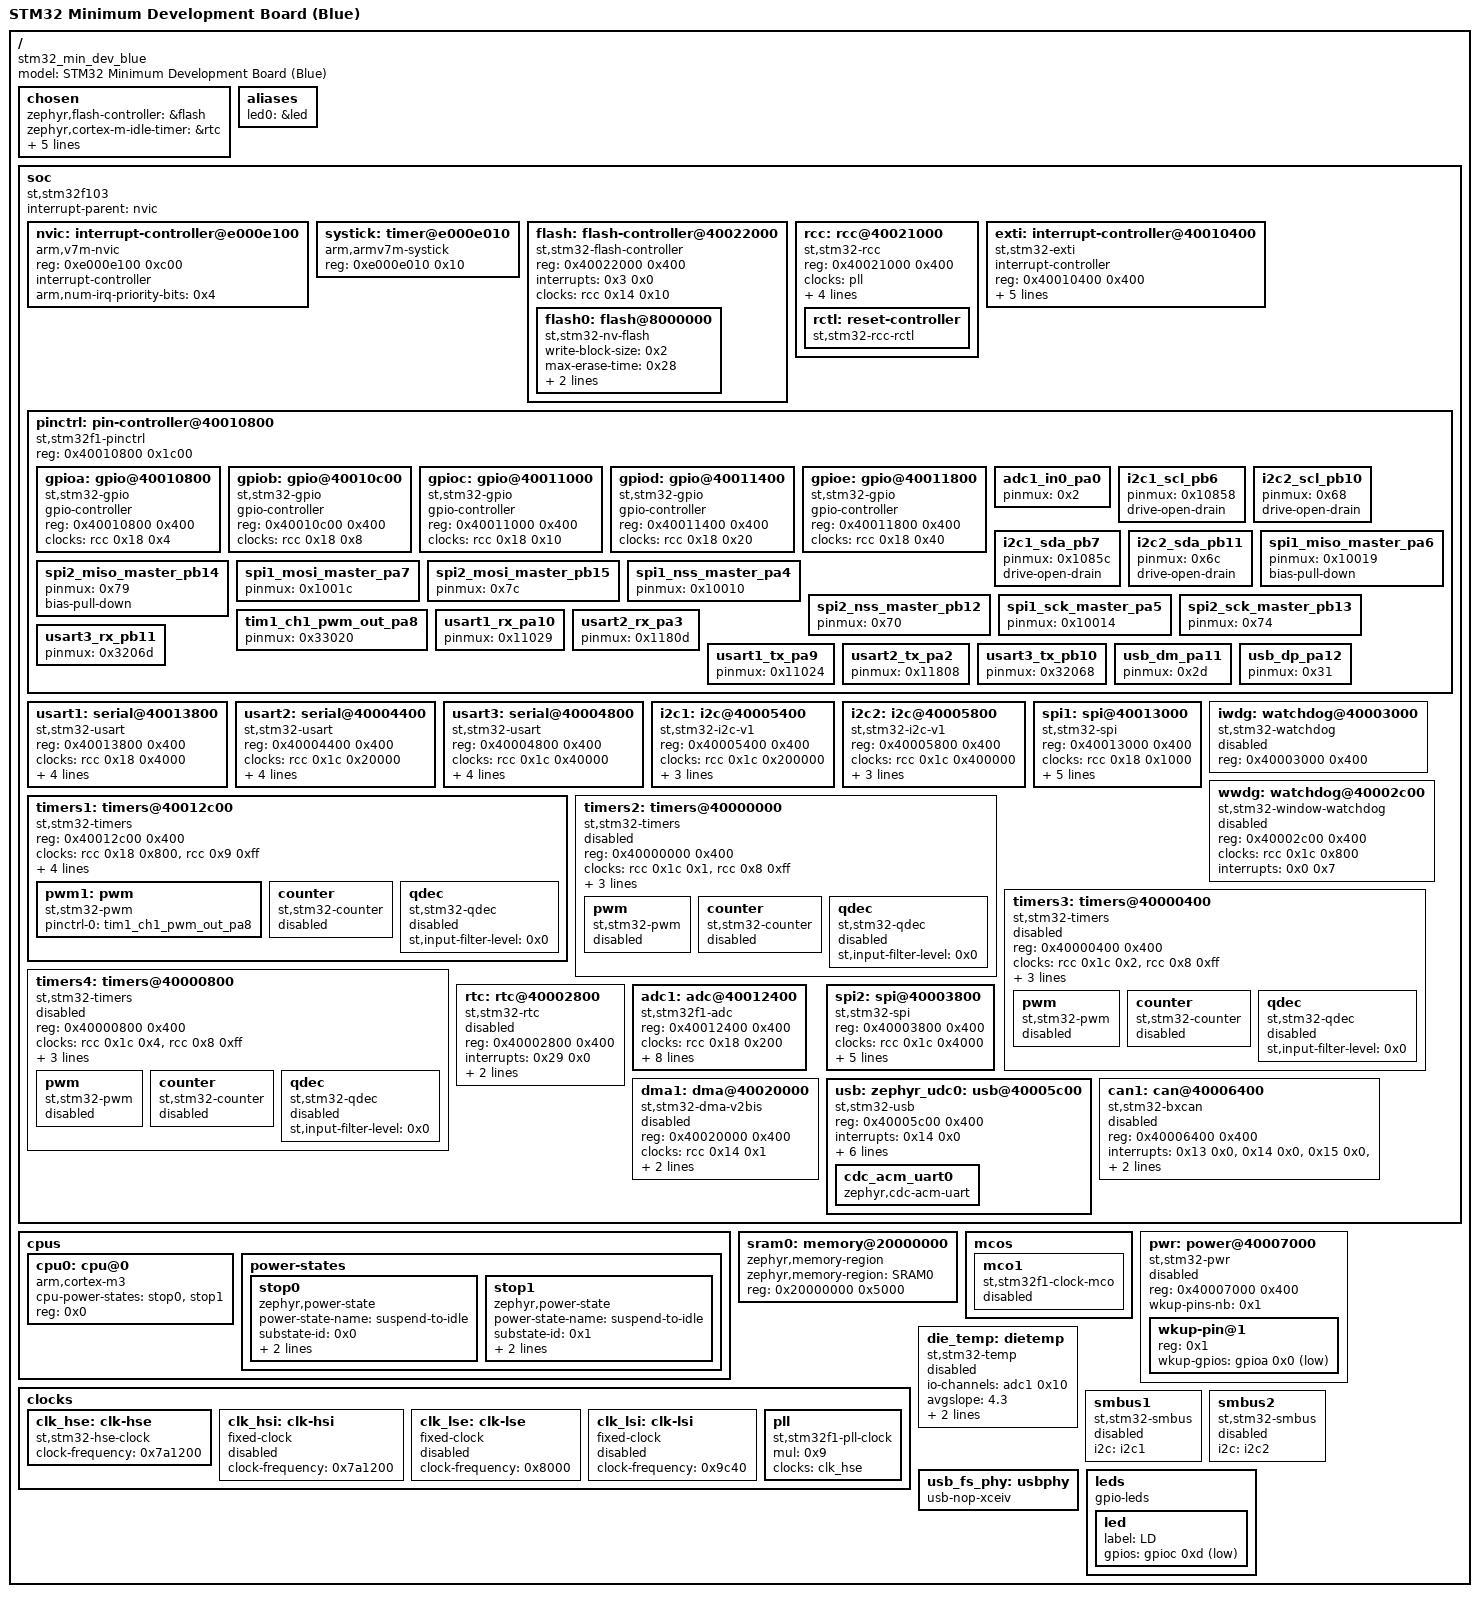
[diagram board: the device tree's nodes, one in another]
/dts-v1/;

/* node '/' defined in zephyr/dts/common/skeleton.dtsi:9 */
/ {
	#address-cells = < 0x1 >;                         /* in zephyr/dts/common/skeleton.dtsi:10 */
	#size-cells = < 0x1 >;                            /* in zephyr/dts/common/skeleton.dtsi:11 */
	model = "STM32 Minimum Development Board (Blue)"; /* in zephyr/boards/others/stm32_min_dev/stm32_min_dev_stm32f103xb_blue.overlay:8 */
	compatible = "stm32_min_dev_blue",
	             "st,stm32f103c8";                    /* in zephyr/boards/others/stm32_min_dev/stm32_min_dev_stm32f103xb_blue.overlay:9 */

	/* node '/chosen' defined in zephyr/dts/common/skeleton.dtsi:13 */
	chosen {
		zephyr,flash-controller = &flash;   /* in zephyr/dts/arm/st/f1/stm32f1.dtsi:24 */
		zephyr,cortex-m-idle-timer = &rtc;  /* in zephyr/dts/arm/st/f1/stm32f1.dtsi:25 */
		zephyr,osdp-uart = &usart2;         /* in zephyr/boards/others/stm32_min_dev/stm32_min_dev.dts:18 */
		zephyr,sram = &sram0;               /* in zephyr/boards/others/stm32_min_dev/stm32_min_dev.dts:19 */
		zephyr,flash = &flash0;             /* in zephyr/boards/others/stm32_min_dev/stm32_min_dev.dts:20 */
		zephyr,console = &cdc_acm_uart0;    /* in zephyer_stm32f103_blink/app.overlay:3 */
		zephyr,shell-uart = &cdc_acm_uart0; /* in zephyer_stm32f103_blink/app.overlay:4 */
	};

	/* node '/aliases' defined in zephyr/dts/common/skeleton.dtsi:15 */
	aliases {
		led0 = &led; /* in zephyr/boards/others/stm32_min_dev/stm32_min_dev.dts:33 */
	};

	/* node '/soc' defined in zephyr/dts/arm/armv7-m.dtsi:6 */
	soc {
		#address-cells = < 0x1 >;     /* in zephyr/dts/arm/armv7-m.dtsi:7 */
		#size-cells = < 0x1 >;        /* in zephyr/dts/arm/armv7-m.dtsi:8 */
		interrupt-parent = < &nvic >; /* in zephyr/dts/arm/armv7-m.dtsi:10 */
		ranges;                       /* in zephyr/dts/arm/armv7-m.dtsi:11 */
		compatible = "st,stm32f103",
		             "st,stm32f1",
		             "simple-bus";    /* in zephyr/dts/arm/st/f1/stm32f103X8.dtsi:15 */

		/* node '/soc/interrupt-controller@e000e100' defined in zephyr/dts/arm/armv7-m.dtsi:13 */
		nvic: interrupt-controller@e000e100 {
			#address-cells = < 0x1 >;            /* in zephyr/dts/arm/armv7-m.dtsi:14 */
			compatible = "arm,v7m-nvic";         /* in zephyr/dts/arm/armv7-m.dtsi:15 */
			reg = < 0xe000e100 0xc00 >;          /* in zephyr/dts/arm/armv7-m.dtsi:16 */
			interrupt-controller;                /* in zephyr/dts/arm/armv7-m.dtsi:17 */
			#interrupt-cells = < 0x2 >;          /* in zephyr/dts/arm/armv7-m.dtsi:18 */
			arm,num-irq-priority-bits = < 0x4 >; /* in zephyr/dts/arm/st/f1/stm32f1.dtsi:466 */
			phandle = < 0x1 >;                   /* in zephyr/dts/arm/armv7-m.dtsi:10 */
		};

		/* node '/soc/timer@e000e010' defined in zephyr/dts/arm/armv7-m.dtsi:21 */
		systick: timer@e000e010 {
			compatible = "arm,armv7m-systick"; /* in zephyr/dts/arm/armv7-m.dtsi:22 */
			reg = < 0xe000e010 0x10 >;         /* in zephyr/dts/arm/armv7-m.dtsi:23 */
		};

		/* node '/soc/flash-controller@40022000' defined in zephyr/dts/arm/st/f1/stm32f1.dtsi:106 */
		flash: flash-controller@40022000 {
			compatible = "st,stm32-flash-controller",
			             "st,stm32f1-flash-controller"; /* in zephyr/dts/arm/st/f1/stm32f1.dtsi:107 */
			reg = < 0x40022000 0x400 >;                 /* in zephyr/dts/arm/st/f1/stm32f1.dtsi:108 */
			interrupts = < 0x3 0x0 >;                   /* in zephyr/dts/arm/st/f1/stm32f1.dtsi:109 */
			clocks = < &rcc 0x14 0x10 >;                /* in zephyr/dts/arm/st/f1/stm32f1.dtsi:110 */
			#address-cells = < 0x1 >;                   /* in zephyr/dts/arm/st/f1/stm32f1.dtsi:112 */
			#size-cells = < 0x1 >;                      /* in zephyr/dts/arm/st/f1/stm32f1.dtsi:113 */

			/* node '/soc/flash-controller@40022000/flash@8000000' defined in zephyr/dts/arm/st/f1/stm32f1.dtsi:115 */
			flash0: flash@8000000 {
				compatible = "st,stm32-nv-flash",
				             "soc-nv-flash";      /* in zephyr/dts/arm/st/f1/stm32f1.dtsi:116 */
				write-block-size = < 0x2 >;       /* in zephyr/dts/arm/st/f1/stm32f1.dtsi:118 */
				max-erase-time = < 0x28 >;        /* in zephyr/dts/arm/st/f1/stm32f1.dtsi:120 */
				reg = < 0x8000000 0x10000 >;      /* in zephyr/dts/arm/st/f1/stm32f103X8.dtsi:19 */
				erase-block-size = < 0x400 >;     /* in zephyr/dts/arm/st/f1/stm32f103X8.dtsi:20 */
			};
		};

		/* node '/soc/rcc@40021000' defined in zephyr/dts/arm/st/f1/stm32f1.dtsi:124 */
		rcc: rcc@40021000 {
			compatible = "st,stm32-rcc";     /* in zephyr/dts/arm/st/f1/stm32f1.dtsi:125 */
			#clock-cells = < 0x2 >;          /* in zephyr/dts/arm/st/f1/stm32f1.dtsi:126 */
			reg = < 0x40021000 0x400 >;      /* in zephyr/dts/arm/st/f1/stm32f1.dtsi:127 */
			clocks = < &pll >;               /* in zephyr/boards/others/stm32_min_dev/stm32_min_dev.dts:49 */
			clock-frequency = < 0x44aa200 >; /* in zephyr/boards/others/stm32_min_dev/stm32_min_dev.dts:50 */
			ahb-prescaler = < 0x1 >;         /* in zephyr/boards/others/stm32_min_dev/stm32_min_dev.dts:51 */
			apb1-prescaler = < 0x2 >;        /* in zephyr/boards/others/stm32_min_dev/stm32_min_dev.dts:52 */
			apb2-prescaler = < 0x1 >;        /* in zephyr/boards/others/stm32_min_dev/stm32_min_dev.dts:53 */
			phandle = < 0x2 >;               /* in zephyr/dts/arm/st/f1/stm32f1.dtsi:110 */

			/* node '/soc/rcc@40021000/reset-controller' defined in zephyr/dts/arm/st/f1/stm32f1.dtsi:129 */
			rctl: reset-controller {
				compatible = "st,stm32-rcc-rctl"; /* in zephyr/dts/arm/st/f1/stm32f1.dtsi:130 */
				#reset-cells = < 0x1 >;           /* in zephyr/dts/arm/st/f1/stm32f1.dtsi:131 */
				phandle = < 0x4 >;                /* in zephyr/dts/arm/st/f1/stm32f1.dtsi:201 */
			};
		};

		/* node '/soc/interrupt-controller@40010400' defined in zephyr/dts/arm/st/f1/stm32f1.dtsi:135 */
		exti: interrupt-controller@40010400 {
			compatible = "st,stm32-exti";  /* in zephyr/dts/arm/st/f1/stm32f1.dtsi:136 */
			interrupt-controller;          /* in zephyr/dts/arm/st/f1/stm32f1.dtsi:137 */
			#interrupt-cells = < 0x1 >;    /* in zephyr/dts/arm/st/f1/stm32f1.dtsi:138 */
			#address-cells = < 0x0 >;      /* in zephyr/dts/arm/st/f1/stm32f1.dtsi:139 */
			reg = < 0x40010400 0x400 >;    /* in zephyr/dts/arm/st/f1/stm32f1.dtsi:140 */
			num-lines = < 0x20 >;          /* in zephyr/dts/arm/st/f1/stm32f1.dtsi:141 */
			interrupts = < 0x6 0x0 >,
			             < 0x7 0x0 >,
			             < 0x8 0x0 >,
			             < 0x9 0x0 >,
			             < 0xa 0x0 >,
			             < 0x17 0x0 >,
			             < 0x28 0x0 >;     /* in zephyr/dts/arm/st/f1/stm32f1.dtsi:142 */
			interrupt-names = "line0",
			                  "line1",
			                  "line2",
			                  "line3",
			                  "line4",
			                  "line5-9",
			                  "line10-15"; /* in zephyr/dts/arm/st/f1/stm32f1.dtsi:144 */
			line-ranges = < 0x0 0x1 >,
			              < 0x1 0x1 >,
			              < 0x2 0x1 >,
			              < 0x3 0x1 >,
			              < 0x4 0x1 >,
			              < 0x5 0x5 >,
			              < 0xa 0x6 >;     /* in zephyr/dts/arm/st/f1/stm32f1.dtsi:146 */
		};

		/* node '/soc/pin-controller@40010800' defined in zephyr/dts/arm/st/f1/stm32f1.dtsi:150 */
		pinctrl: pin-controller@40010800 {
			compatible = "st,stm32f1-pinctrl"; /* in zephyr/dts/arm/st/f1/stm32f1.dtsi:151 */
			#address-cells = < 0x1 >;          /* in zephyr/dts/arm/st/f1/stm32f1.dtsi:152 */
			#size-cells = < 0x1 >;             /* in zephyr/dts/arm/st/f1/stm32f1.dtsi:153 */
			reg = < 0x40010800 0x1c00 >;       /* in zephyr/dts/arm/st/f1/stm32f1.dtsi:154 */

			/* node '/soc/pin-controller@40010800/gpio@40010800' defined in zephyr/dts/arm/st/f1/stm32f1.dtsi:156 */
			gpioa: gpio@40010800 {
				compatible = "st,stm32-gpio"; /* in zephyr/dts/arm/st/f1/stm32f1.dtsi:157 */
				gpio-controller;              /* in zephyr/dts/arm/st/f1/stm32f1.dtsi:158 */
				#gpio-cells = < 0x2 >;        /* in zephyr/dts/arm/st/f1/stm32f1.dtsi:159 */
				reg = < 0x40010800 0x400 >;   /* in zephyr/dts/arm/st/f1/stm32f1.dtsi:160 */
				clocks = < &rcc 0x18 0x4 >;   /* in zephyr/dts/arm/st/f1/stm32f1.dtsi:161 */
				phandle = < 0x1f >;           /* in zephyr/dts/arm/st/f1/stm32f1.dtsi:435 */
			};

			/* node '/soc/pin-controller@40010800/gpio@40010c00' defined in zephyr/dts/arm/st/f1/stm32f1.dtsi:164 */
			gpiob: gpio@40010c00 {
				compatible = "st,stm32-gpio"; /* in zephyr/dts/arm/st/f1/stm32f1.dtsi:165 */
				gpio-controller;              /* in zephyr/dts/arm/st/f1/stm32f1.dtsi:166 */
				#gpio-cells = < 0x2 >;        /* in zephyr/dts/arm/st/f1/stm32f1.dtsi:167 */
				reg = < 0x40010c00 0x400 >;   /* in zephyr/dts/arm/st/f1/stm32f1.dtsi:168 */
				clocks = < &rcc 0x18 0x8 >;   /* in zephyr/dts/arm/st/f1/stm32f1.dtsi:169 */
			};

			/* node '/soc/pin-controller@40010800/gpio@40011000' defined in zephyr/dts/arm/st/f1/stm32f1.dtsi:172 */
			gpioc: gpio@40011000 {
				compatible = "st,stm32-gpio"; /* in zephyr/dts/arm/st/f1/stm32f1.dtsi:173 */
				gpio-controller;              /* in zephyr/dts/arm/st/f1/stm32f1.dtsi:174 */
				#gpio-cells = < 0x2 >;        /* in zephyr/dts/arm/st/f1/stm32f1.dtsi:175 */
				reg = < 0x40011000 0x400 >;   /* in zephyr/dts/arm/st/f1/stm32f1.dtsi:176 */
				clocks = < &rcc 0x18 0x10 >;  /* in zephyr/dts/arm/st/f1/stm32f1.dtsi:177 */
				phandle = < 0x23 >;           /* in zephyr/boards/others/stm32_min_dev/stm32_min_dev_stm32f103xb_blue.overlay:13 */
			};

			/* node '/soc/pin-controller@40010800/gpio@40011400' defined in zephyr/dts/arm/st/f1/stm32f1.dtsi:180 */
			gpiod: gpio@40011400 {
				compatible = "st,stm32-gpio"; /* in zephyr/dts/arm/st/f1/stm32f1.dtsi:181 */
				gpio-controller;              /* in zephyr/dts/arm/st/f1/stm32f1.dtsi:182 */
				#gpio-cells = < 0x2 >;        /* in zephyr/dts/arm/st/f1/stm32f1.dtsi:183 */
				reg = < 0x40011400 0x400 >;   /* in zephyr/dts/arm/st/f1/stm32f1.dtsi:184 */
				clocks = < &rcc 0x18 0x20 >;  /* in zephyr/dts/arm/st/f1/stm32f1.dtsi:185 */
			};

			/* node '/soc/pin-controller@40010800/gpio@40011800' defined in zephyr/dts/arm/st/f1/stm32f1.dtsi:188 */
			gpioe: gpio@40011800 {
				compatible = "st,stm32-gpio"; /* in zephyr/dts/arm/st/f1/stm32f1.dtsi:189 */
				gpio-controller;              /* in zephyr/dts/arm/st/f1/stm32f1.dtsi:190 */
				#gpio-cells = < 0x2 >;        /* in zephyr/dts/arm/st/f1/stm32f1.dtsi:191 */
				reg = < 0x40011800 0x400 >;   /* in zephyr/dts/arm/st/f1/stm32f1.dtsi:192 */
				clocks = < &rcc 0x18 0x40 >;  /* in zephyr/dts/arm/st/f1/stm32f1.dtsi:193 */
			};

			/* node '/soc/pin-controller@40010800/adc1_in0_pa0' defined in modules/hal/stm32/dts/st/f1/stm32f103r(8-b)tx-pinctrl.dtsi:15 */
			adc1_in0_pa0: adc1_in0_pa0 {
				pinmux = < 0x2 >;   /* in modules/hal/stm32/dts/st/f1/stm32f103r(8-b)tx-pinctrl.dtsi:16 */
				phandle = < 0x14 >; /* in zephyr/boards/others/stm32_min_dev/stm32_min_dev.dts:123 */
			};

			/* node '/soc/pin-controller@40010800/i2c1_scl_pb6' defined in modules/hal/stm32/dts/st/f1/stm32f103r(8-b)tx-pinctrl.dtsi:371 */
			i2c1_scl_pb6: i2c1_scl_pb6 {
				pinmux = < 0x10858 >; /* in modules/hal/stm32/dts/st/f1/stm32f103r(8-b)tx-pinctrl.dtsi:372 */
				drive-open-drain;     /* in modules/hal/stm32/dts/st/f1/stm32f103r(8-b)tx-pinctrl.dtsi:373 */
				phandle = < 0xb >;    /* in zephyr/boards/others/stm32_min_dev/stm32_min_dev.dts:79 */
			};

			/* node '/soc/pin-controller@40010800/i2c2_scl_pb10' defined in modules/hal/stm32/dts/st/f1/stm32f103r(8-b)tx-pinctrl.dtsi:381 */
			i2c2_scl_pb10: i2c2_scl_pb10 {
				pinmux = < 0x68 >; /* in modules/hal/stm32/dts/st/f1/stm32f103r(8-b)tx-pinctrl.dtsi:382 */
				drive-open-drain;  /* in modules/hal/stm32/dts/st/f1/stm32f103r(8-b)tx-pinctrl.dtsi:383 */
				phandle = < 0xd >; /* in zephyr/boards/others/stm32_min_dev/stm32_min_dev.dts:86 */
			};

			/* node '/soc/pin-controller@40010800/i2c1_sda_pb7' defined in modules/hal/stm32/dts/st/f1/stm32f103r(8-b)tx-pinctrl.dtsi:388 */
			i2c1_sda_pb7: i2c1_sda_pb7 {
				pinmux = < 0x1085c >; /* in modules/hal/stm32/dts/st/f1/stm32f103r(8-b)tx-pinctrl.dtsi:389 */
				drive-open-drain;     /* in modules/hal/stm32/dts/st/f1/stm32f103r(8-b)tx-pinctrl.dtsi:390 */
				phandle = < 0xc >;    /* in zephyr/boards/others/stm32_min_dev/stm32_min_dev.dts:79 */
			};

			/* node '/soc/pin-controller@40010800/i2c2_sda_pb11' defined in modules/hal/stm32/dts/st/f1/stm32f103r(8-b)tx-pinctrl.dtsi:398 */
			i2c2_sda_pb11: i2c2_sda_pb11 {
				pinmux = < 0x6c >; /* in modules/hal/stm32/dts/st/f1/stm32f103r(8-b)tx-pinctrl.dtsi:399 */
				drive-open-drain;  /* in modules/hal/stm32/dts/st/f1/stm32f103r(8-b)tx-pinctrl.dtsi:400 */
				phandle = < 0xe >; /* in zephyr/boards/others/stm32_min_dev/stm32_min_dev.dts:86 */
			};

			/* node '/soc/pin-controller@40010800/spi1_miso_master_pa6' defined in modules/hal/stm32/dts/st/f1/stm32f103r(8-b)tx-pinctrl.dtsi:439 */
			spi1_miso_master_pa6: spi1_miso_master_pa6 {
				pinmux = < 0x10019 >; /* in modules/hal/stm32/dts/st/f1/stm32f103r(8-b)tx-pinctrl.dtsi:440 */
				bias-pull-down;       /* in modules/hal/stm32/dts/st/f1/stm32f103r(8-b)tx-pinctrl.dtsi:441 */
				phandle = < 0x11 >;   /* in zephyr/boards/others/stm32_min_dev/stm32_min_dev.dts:93 */
			};

			/* node '/soc/pin-controller@40010800/spi2_miso_master_pb14' defined in modules/hal/stm32/dts/st/f1/stm32f103r(8-b)tx-pinctrl.dtsi:449 */
			spi2_miso_master_pb14: spi2_miso_master_pb14 {
				pinmux = < 0x79 >;  /* in modules/hal/stm32/dts/st/f1/stm32f103r(8-b)tx-pinctrl.dtsi:450 */
				bias-pull-down;     /* in modules/hal/stm32/dts/st/f1/stm32f103r(8-b)tx-pinctrl.dtsi:451 */
				phandle = < 0x17 >; /* in zephyr/boards/others/stm32_min_dev/stm32_min_dev.dts:100 */
			};

			/* node '/soc/pin-controller@40010800/spi1_mosi_master_pa7' defined in modules/hal/stm32/dts/st/f1/stm32f103r(8-b)tx-pinctrl.dtsi:456 */
			spi1_mosi_master_pa7: spi1_mosi_master_pa7 {
				pinmux = < 0x1001c >; /* in modules/hal/stm32/dts/st/f1/stm32f103r(8-b)tx-pinctrl.dtsi:457 */
				phandle = < 0x12 >;   /* in zephyr/boards/others/stm32_min_dev/stm32_min_dev.dts:93 */
			};

			/* node '/soc/pin-controller@40010800/spi2_mosi_master_pb15' defined in modules/hal/stm32/dts/st/f1/stm32f103r(8-b)tx-pinctrl.dtsi:464 */
			spi2_mosi_master_pb15: spi2_mosi_master_pb15 {
				pinmux = < 0x7c >;  /* in modules/hal/stm32/dts/st/f1/stm32f103r(8-b)tx-pinctrl.dtsi:465 */
				phandle = < 0x18 >; /* in zephyr/boards/others/stm32_min_dev/stm32_min_dev.dts:100 */
			};

			/* node '/soc/pin-controller@40010800/spi1_nss_master_pa4' defined in modules/hal/stm32/dts/st/f1/stm32f103r(8-b)tx-pinctrl.dtsi:470 */
			spi1_nss_master_pa4: spi1_nss_master_pa4 {
				pinmux = < 0x10010 >; /* in modules/hal/stm32/dts/st/f1/stm32f103r(8-b)tx-pinctrl.dtsi:471 */
				phandle = < 0xf >;    /* in zephyr/boards/others/stm32_min_dev/stm32_min_dev.dts:93 */
			};

			/* node '/soc/pin-controller@40010800/spi2_nss_master_pb12' defined in modules/hal/stm32/dts/st/f1/stm32f103r(8-b)tx-pinctrl.dtsi:478 */
			spi2_nss_master_pb12: spi2_nss_master_pb12 {
				pinmux = < 0x70 >;  /* in modules/hal/stm32/dts/st/f1/stm32f103r(8-b)tx-pinctrl.dtsi:479 */
				phandle = < 0x15 >; /* in zephyr/boards/others/stm32_min_dev/stm32_min_dev.dts:100 */
			};

			/* node '/soc/pin-controller@40010800/spi1_sck_master_pa5' defined in modules/hal/stm32/dts/st/f1/stm32f103r(8-b)tx-pinctrl.dtsi:484 */
			spi1_sck_master_pa5: spi1_sck_master_pa5 {
				pinmux = < 0x10014 >; /* in modules/hal/stm32/dts/st/f1/stm32f103r(8-b)tx-pinctrl.dtsi:485 */
				phandle = < 0x10 >;   /* in zephyr/boards/others/stm32_min_dev/stm32_min_dev.dts:93 */
			};

			/* node '/soc/pin-controller@40010800/spi2_sck_master_pb13' defined in modules/hal/stm32/dts/st/f1/stm32f103r(8-b)tx-pinctrl.dtsi:492 */
			spi2_sck_master_pb13: spi2_sck_master_pb13 {
				pinmux = < 0x74 >;  /* in modules/hal/stm32/dts/st/f1/stm32f103r(8-b)tx-pinctrl.dtsi:493 */
				phandle = < 0x16 >; /* in zephyr/boards/others/stm32_min_dev/stm32_min_dev.dts:100 */
			};

			/* node '/soc/pin-controller@40010800/tim1_ch1_pwm_out_pa8' defined in modules/hal/stm32/dts/st/f1/stm32f103r(8-b)tx-pinctrl.dtsi:757 */
			tim1_ch1_pwm_out_pa8: tim1_ch1_pwm_out_pa8 {
				pinmux = < 0x33020 >; /* in modules/hal/stm32/dts/st/f1/stm32f103r(8-b)tx-pinctrl.dtsi:758 */
				phandle = < 0x13 >;   /* in zephyr/boards/others/stm32_min_dev/stm32_min_dev.dts:111 */
			};

			/* node '/soc/pin-controller@40010800/usart1_rx_pa10' defined in modules/hal/stm32/dts/st/f1/stm32f103r(8-b)tx-pinctrl.dtsi:983 */
			usart1_rx_pa10: usart1_rx_pa10 {
				pinmux = < 0x11029 >; /* in modules/hal/stm32/dts/st/f1/stm32f103r(8-b)tx-pinctrl.dtsi:984 */
				phandle = < 0x6 >;    /* in zephyr/boards/others/stm32_min_dev/stm32_min_dev.dts:58 */
			};

			/* node '/soc/pin-controller@40010800/usart2_rx_pa3' defined in modules/hal/stm32/dts/st/f1/stm32f103r(8-b)tx-pinctrl.dtsi:991 */
			usart2_rx_pa3: usart2_rx_pa3 {
				pinmux = < 0x1180d >; /* in modules/hal/stm32/dts/st/f1/stm32f103r(8-b)tx-pinctrl.dtsi:992 */
				phandle = < 0x8 >;    /* in zephyr/boards/others/stm32_min_dev/stm32_min_dev.dts:65 */
			};

			/* node '/soc/pin-controller@40010800/usart3_rx_pb11' defined in modules/hal/stm32/dts/st/f1/stm32f103r(8-b)tx-pinctrl.dtsi:995 */
			usart3_rx_pb11: usart3_rx_pb11 {
				pinmux = < 0x3206d >; /* in modules/hal/stm32/dts/st/f1/stm32f103r(8-b)tx-pinctrl.dtsi:996 */
				phandle = < 0xa >;    /* in zephyr/boards/others/stm32_min_dev/stm32_min_dev.dts:72 */
			};

			/* node '/soc/pin-controller@40010800/usart1_tx_pa9' defined in modules/hal/stm32/dts/st/f1/stm32f103r(8-b)tx-pinctrl.dtsi:1005 */
			usart1_tx_pa9: usart1_tx_pa9 {
				pinmux = < 0x11024 >; /* in modules/hal/stm32/dts/st/f1/stm32f103r(8-b)tx-pinctrl.dtsi:1006 */
				phandle = < 0x5 >;    /* in zephyr/boards/others/stm32_min_dev/stm32_min_dev.dts:58 */
			};

			/* node '/soc/pin-controller@40010800/usart2_tx_pa2' defined in modules/hal/stm32/dts/st/f1/stm32f103r(8-b)tx-pinctrl.dtsi:1013 */
			usart2_tx_pa2: usart2_tx_pa2 {
				pinmux = < 0x11808 >; /* in modules/hal/stm32/dts/st/f1/stm32f103r(8-b)tx-pinctrl.dtsi:1014 */
				phandle = < 0x7 >;    /* in zephyr/boards/others/stm32_min_dev/stm32_min_dev.dts:65 */
			};

			/* node '/soc/pin-controller@40010800/usart3_tx_pb10' defined in modules/hal/stm32/dts/st/f1/stm32f103r(8-b)tx-pinctrl.dtsi:1017 */
			usart3_tx_pb10: usart3_tx_pb10 {
				pinmux = < 0x32068 >; /* in modules/hal/stm32/dts/st/f1/stm32f103r(8-b)tx-pinctrl.dtsi:1018 */
				phandle = < 0x9 >;    /* in zephyr/boards/others/stm32_min_dev/stm32_min_dev.dts:72 */
			};

			/* node '/soc/pin-controller@40010800/usb_dm_pa11' defined in modules/hal/stm32/dts/st/f1/stm32f103r(8-b)tx-pinctrl.dtsi:1027 */
			usb_dm_pa11: usb_dm_pa11 {
				pinmux = < 0x2d >;  /* in modules/hal/stm32/dts/st/f1/stm32f103r(8-b)tx-pinctrl.dtsi:1028 */
				phandle = < 0x1a >; /* in zephyr/boards/others/stm32_min_dev/stm32_min_dev.dts:117 */
			};

			/* node '/soc/pin-controller@40010800/usb_dp_pa12' defined in modules/hal/stm32/dts/st/f1/stm32f103r(8-b)tx-pinctrl.dtsi:1031 */
			usb_dp_pa12: usb_dp_pa12 {
				pinmux = < 0x31 >;  /* in modules/hal/stm32/dts/st/f1/stm32f103r(8-b)tx-pinctrl.dtsi:1032 */
				phandle = < 0x1b >; /* in zephyr/boards/others/stm32_min_dev/stm32_min_dev.dts:117 */
			};
		};

		/* node '/soc/serial@40013800' defined in zephyr/dts/arm/st/f1/stm32f1.dtsi:197 */
		usart1: serial@40013800 {
			compatible = "st,stm32-usart",
			             "st,stm32-uart";                   /* in zephyr/dts/arm/st/f1/stm32f1.dtsi:198 */
			reg = < 0x40013800 0x400 >;                     /* in zephyr/dts/arm/st/f1/stm32f1.dtsi:199 */
			clocks = < &rcc 0x18 0x4000 >;                  /* in zephyr/dts/arm/st/f1/stm32f1.dtsi:200 */
			resets = < &rctl 0x18e >;                       /* in zephyr/dts/arm/st/f1/stm32f1.dtsi:201 */
			interrupts = < 0x25 0x0 >;                      /* in zephyr/dts/arm/st/f1/stm32f1.dtsi:202 */
			pinctrl-0 = < &usart1_tx_pa9 &usart1_rx_pa10 >; /* in zephyr/boards/others/stm32_min_dev/stm32_min_dev.dts:58 */
			current-speed = < 0x1c200 >;                    /* in zephyr/boards/others/stm32_min_dev/stm32_min_dev.dts:59 */
			pinctrl-names = "default";                      /* in zephyr/boards/others/stm32_min_dev/stm32_min_dev.dts:60 */
			status = "okay";                                /* in zephyr/boards/others/stm32_min_dev/stm32_min_dev.dts:61 */
		};

		/* node '/soc/serial@40004400' defined in zephyr/dts/arm/st/f1/stm32f1.dtsi:206 */
		usart2: serial@40004400 {
			compatible = "st,stm32-usart",
			             "st,stm32-uart";                  /* in zephyr/dts/arm/st/f1/stm32f1.dtsi:207 */
			reg = < 0x40004400 0x400 >;                    /* in zephyr/dts/arm/st/f1/stm32f1.dtsi:208 */
			clocks = < &rcc 0x1c 0x20000 >;                /* in zephyr/dts/arm/st/f1/stm32f1.dtsi:209 */
			resets = < &rctl 0x211 >;                      /* in zephyr/dts/arm/st/f1/stm32f1.dtsi:210 */
			interrupts = < 0x26 0x0 >;                     /* in zephyr/dts/arm/st/f1/stm32f1.dtsi:211 */
			pinctrl-0 = < &usart2_tx_pa2 &usart2_rx_pa3 >; /* in zephyr/boards/others/stm32_min_dev/stm32_min_dev.dts:65 */
			current-speed = < 0x1c200 >;                   /* in zephyr/boards/others/stm32_min_dev/stm32_min_dev.dts:66 */
			pinctrl-names = "default";                     /* in zephyr/boards/others/stm32_min_dev/stm32_min_dev.dts:67 */
			status = "okay";                               /* in zephyr/boards/others/stm32_min_dev/stm32_min_dev.dts:68 */
		};

		/* node '/soc/serial@40004800' defined in zephyr/dts/arm/st/f1/stm32f1.dtsi:215 */
		usart3: serial@40004800 {
			compatible = "st,stm32-usart",
			             "st,stm32-uart";                    /* in zephyr/dts/arm/st/f1/stm32f1.dtsi:216 */
			reg = < 0x40004800 0x400 >;                      /* in zephyr/dts/arm/st/f1/stm32f1.dtsi:217 */
			clocks = < &rcc 0x1c 0x40000 >;                  /* in zephyr/dts/arm/st/f1/stm32f1.dtsi:218 */
			resets = < &rctl 0x212 >;                        /* in zephyr/dts/arm/st/f1/stm32f1.dtsi:219 */
			interrupts = < 0x27 0x0 >;                       /* in zephyr/dts/arm/st/f1/stm32f1.dtsi:220 */
			pinctrl-0 = < &usart3_tx_pb10 &usart3_rx_pb11 >; /* in zephyr/boards/others/stm32_min_dev/stm32_min_dev.dts:72 */
			current-speed = < 0x1c200 >;                     /* in zephyr/boards/others/stm32_min_dev/stm32_min_dev.dts:73 */
			pinctrl-names = "default";                       /* in zephyr/boards/others/stm32_min_dev/stm32_min_dev.dts:74 */
			status = "okay";                                 /* in zephyr/boards/others/stm32_min_dev/stm32_min_dev.dts:75 */
		};

		/* node '/soc/i2c@40005400' defined in zephyr/dts/arm/st/f1/stm32f1.dtsi:224 */
		i2c1: i2c@40005400 {
			compatible = "st,stm32-i2c-v1";              /* in zephyr/dts/arm/st/f1/stm32f1.dtsi:225 */
			#address-cells = < 0x1 >;                    /* in zephyr/dts/arm/st/f1/stm32f1.dtsi:227 */
			#size-cells = < 0x0 >;                       /* in zephyr/dts/arm/st/f1/stm32f1.dtsi:228 */
			reg = < 0x40005400 0x400 >;                  /* in zephyr/dts/arm/st/f1/stm32f1.dtsi:229 */
			clocks = < &rcc 0x1c 0x200000 >;             /* in zephyr/dts/arm/st/f1/stm32f1.dtsi:230 */
			interrupts = < 0x1f 0x0 >,
			             < 0x20 0x0 >;                   /* in zephyr/dts/arm/st/f1/stm32f1.dtsi:231 */
			interrupt-names = "event",
			                  "error";                   /* in zephyr/dts/arm/st/f1/stm32f1.dtsi:232 */
			pinctrl-0 = < &i2c1_scl_pb6 &i2c1_sda_pb7 >; /* in zephyr/boards/others/stm32_min_dev/stm32_min_dev.dts:79 */
			status = "okay";                             /* in zephyr/boards/others/stm32_min_dev/stm32_min_dev.dts:80 */
			pinctrl-names = "default";                   /* in zephyr/boards/others/stm32_min_dev/stm32_min_dev.dts:81 */
			clock-frequency = < 0x61a80 >;               /* in zephyr/boards/others/stm32_min_dev/stm32_min_dev.dts:82 */
			phandle = < 0x21 >;                          /* in zephyr/dts/arm/st/f1/stm32f1.dtsi:452 */
		};

		/* node '/soc/i2c@40005800' defined in zephyr/dts/arm/st/f1/stm32f1.dtsi:236 */
		i2c2: i2c@40005800 {
			compatible = "st,stm32-i2c-v1";                /* in zephyr/dts/arm/st/f1/stm32f1.dtsi:237 */
			#address-cells = < 0x1 >;                      /* in zephyr/dts/arm/st/f1/stm32f1.dtsi:239 */
			#size-cells = < 0x0 >;                         /* in zephyr/dts/arm/st/f1/stm32f1.dtsi:240 */
			reg = < 0x40005800 0x400 >;                    /* in zephyr/dts/arm/st/f1/stm32f1.dtsi:241 */
			clocks = < &rcc 0x1c 0x400000 >;               /* in zephyr/dts/arm/st/f1/stm32f1.dtsi:242 */
			interrupts = < 0x21 0x0 >,
			             < 0x22 0x0 >;                     /* in zephyr/dts/arm/st/f1/stm32f1.dtsi:243 */
			interrupt-names = "event",
			                  "error";                     /* in zephyr/dts/arm/st/f1/stm32f1.dtsi:244 */
			pinctrl-0 = < &i2c2_scl_pb10 &i2c2_sda_pb11 >; /* in zephyr/boards/others/stm32_min_dev/stm32_min_dev.dts:86 */
			pinctrl-names = "default";                     /* in zephyr/boards/others/stm32_min_dev/stm32_min_dev.dts:87 */
			status = "okay";                               /* in zephyr/boards/others/stm32_min_dev/stm32_min_dev.dts:88 */
			clock-frequency = < 0x61a80 >;                 /* in zephyr/boards/others/stm32_min_dev/stm32_min_dev.dts:89 */
			phandle = < 0x22 >;                            /* in zephyr/dts/arm/st/f1/stm32f1.dtsi:460 */
		};

		/* node '/soc/spi@40013000' defined in zephyr/dts/arm/st/f1/stm32f1.dtsi:248 */
		spi1: spi@40013000 {
			compatible = "st,stm32-spi";                                                                           /* in zephyr/dts/arm/st/f1/stm32f1.dtsi:249 */
			#address-cells = < 0x1 >;                                                                              /* in zephyr/dts/arm/st/f1/stm32f1.dtsi:250 */
			#size-cells = < 0x0 >;                                                                                 /* in zephyr/dts/arm/st/f1/stm32f1.dtsi:251 */
			reg = < 0x40013000 0x400 >;                                                                            /* in zephyr/dts/arm/st/f1/stm32f1.dtsi:252 */
			clocks = < &rcc 0x18 0x1000 >;                                                                         /* in zephyr/dts/arm/st/f1/stm32f1.dtsi:253 */
			interrupts = < 0x23 0x5 >;                                                                             /* in zephyr/dts/arm/st/f1/stm32f1.dtsi:254 */
			st,spi-data-width = "limited-8-16-bit";                                                                /* in zephyr/dts/arm/st/f1/stm32f1.dtsi:255 */
			pinctrl-0 = < &spi1_nss_master_pa4 &spi1_sck_master_pa5 &spi1_miso_master_pa6 &spi1_mosi_master_pa7 >; /* in zephyr/boards/others/stm32_min_dev/stm32_min_dev.dts:93 */
			pinctrl-names = "default";                                                                             /* in zephyr/boards/others/stm32_min_dev/stm32_min_dev.dts:95 */
			status = "okay";                                                                                       /* in zephyr/boards/others/stm32_min_dev/stm32_min_dev.dts:96 */
		};

		/* node '/soc/watchdog@40003000' defined in zephyr/dts/arm/st/f1/stm32f1.dtsi:259 */
		iwdg: watchdog@40003000 {
			compatible = "st,stm32-watchdog"; /* in zephyr/dts/arm/st/f1/stm32f1.dtsi:260 */
			reg = < 0x40003000 0x400 >;       /* in zephyr/dts/arm/st/f1/stm32f1.dtsi:261 */
			status = "disabled";              /* in zephyr/dts/arm/st/f1/stm32f1.dtsi:262 */
		};

		/* node '/soc/watchdog@40002c00' defined in zephyr/dts/arm/st/f1/stm32f1.dtsi:265 */
		wwdg: watchdog@40002c00 {
			compatible = "st,stm32-window-watchdog"; /* in zephyr/dts/arm/st/f1/stm32f1.dtsi:266 */
			reg = < 0x40002c00 0x400 >;              /* in zephyr/dts/arm/st/f1/stm32f1.dtsi:267 */
			clocks = < &rcc 0x1c 0x800 >;            /* in zephyr/dts/arm/st/f1/stm32f1.dtsi:268 */
			interrupts = < 0x0 0x7 >;                /* in zephyr/dts/arm/st/f1/stm32f1.dtsi:269 */
			status = "disabled";                     /* in zephyr/dts/arm/st/f1/stm32f1.dtsi:270 */
		};

		/* node '/soc/timers@40012c00' defined in zephyr/dts/arm/st/f1/stm32f1.dtsi:273 */
		timers1: timers@40012c00 {
			compatible = "st,stm32-timers"; /* in zephyr/dts/arm/st/f1/stm32f1.dtsi:274 */
			reg = < 0x40012c00 0x400 >;     /* in zephyr/dts/arm/st/f1/stm32f1.dtsi:275 */
			clocks = < &rcc 0x18 0x800 >,
			         < &rcc 0x9 0xff >;     /* in zephyr/dts/arm/st/f1/stm32f1.dtsi:276 */
			resets = < &rctl 0x18b >;       /* in zephyr/dts/arm/st/f1/stm32f1.dtsi:278 */
			interrupts = < 0x18 0x0 >,
			             < 0x19 0x0 >,
			             < 0x1a 0x0 >,
			             < 0x1b 0x0 >;      /* in zephyr/dts/arm/st/f1/stm32f1.dtsi:279 */
			interrupt-names = "brk",
			                  "up",
			                  "trgcom",
			                  "cc";         /* in zephyr/dts/arm/st/f1/stm32f1.dtsi:280 */
			st,prescaler = < 0x0 >;         /* in zephyr/dts/arm/st/f1/stm32f1.dtsi:281 */
			status = "okay";                /* in zephyr/boards/others/stm32_min_dev/stm32_min_dev.dts:107 */

			/* node '/soc/timers@40012c00/pwm' defined in zephyr/dts/arm/st/f1/stm32f1.dtsi:284 */
			pwm1: pwm {
				compatible = "st,stm32-pwm";           /* in zephyr/dts/arm/st/f1/stm32f1.dtsi:285 */
				#pwm-cells = < 0x3 >;                  /* in zephyr/dts/arm/st/f1/stm32f1.dtsi:287 */
				status = "okay";                       /* in zephyr/boards/others/stm32_min_dev/stm32_min_dev.dts:110 */
				pinctrl-0 = < &tim1_ch1_pwm_out_pa8 >; /* in zephyr/boards/others/stm32_min_dev/stm32_min_dev.dts:111 */
				pinctrl-names = "default";             /* in zephyr/boards/others/stm32_min_dev/stm32_min_dev.dts:112 */
			};

			/* node '/soc/timers@40012c00/counter' defined in zephyr/dts/arm/st/f1/stm32f1.dtsi:290 */
			counter {
				compatible = "st,stm32-counter"; /* in zephyr/dts/arm/st/f1/stm32f1.dtsi:291 */
				status = "disabled";             /* in zephyr/dts/arm/st/f1/stm32f1.dtsi:292 */
			};

			/* node '/soc/timers@40012c00/qdec' defined in zephyr/dts/arm/st/f1/stm32f1.dtsi:295 */
			qdec {
				compatible = "st,stm32-qdec";    /* in zephyr/dts/arm/st/f1/stm32f1.dtsi:296 */
				st,input-filter-level = < 0x0 >; /* in zephyr/dts/arm/st/f1/stm32f1.dtsi:297 */
				status = "disabled";             /* in zephyr/dts/arm/st/f1/stm32f1.dtsi:298 */
			};
		};

		/* node '/soc/timers@40000000' defined in zephyr/dts/arm/st/f1/stm32f1.dtsi:302 */
		timers2: timers@40000000 {
			compatible = "st,stm32-timers"; /* in zephyr/dts/arm/st/f1/stm32f1.dtsi:303 */
			reg = < 0x40000000 0x400 >;     /* in zephyr/dts/arm/st/f1/stm32f1.dtsi:304 */
			clocks = < &rcc 0x1c 0x1 >,
			         < &rcc 0x8 0xff >;     /* in zephyr/dts/arm/st/f1/stm32f1.dtsi:305 */
			resets = < &rctl 0x200 >;       /* in zephyr/dts/arm/st/f1/stm32f1.dtsi:307 */
			interrupts = < 0x1c 0x0 >;      /* in zephyr/dts/arm/st/f1/stm32f1.dtsi:308 */
			interrupt-names = "global";     /* in zephyr/dts/arm/st/f1/stm32f1.dtsi:309 */
			st,prescaler = < 0x0 >;         /* in zephyr/dts/arm/st/f1/stm32f1.dtsi:310 */
			status = "disabled";            /* in zephyr/dts/arm/st/f1/stm32f1.dtsi:311 */

			/* node '/soc/timers@40000000/pwm' defined in zephyr/dts/arm/st/f1/stm32f1.dtsi:313 */
			pwm {
				compatible = "st,stm32-pwm"; /* in zephyr/dts/arm/st/f1/stm32f1.dtsi:314 */
				status = "disabled";         /* in zephyr/dts/arm/st/f1/stm32f1.dtsi:315 */
				#pwm-cells = < 0x3 >;        /* in zephyr/dts/arm/st/f1/stm32f1.dtsi:316 */
			};

			/* node '/soc/timers@40000000/counter' defined in zephyr/dts/arm/st/f1/stm32f1.dtsi:319 */
			counter {
				compatible = "st,stm32-counter"; /* in zephyr/dts/arm/st/f1/stm32f1.dtsi:320 */
				status = "disabled";             /* in zephyr/dts/arm/st/f1/stm32f1.dtsi:321 */
			};

			/* node '/soc/timers@40000000/qdec' defined in zephyr/dts/arm/st/f1/stm32f1.dtsi:324 */
			qdec {
				compatible = "st,stm32-qdec";    /* in zephyr/dts/arm/st/f1/stm32f1.dtsi:325 */
				st,input-filter-level = < 0x0 >; /* in zephyr/dts/arm/st/f1/stm32f1.dtsi:326 */
				status = "disabled";             /* in zephyr/dts/arm/st/f1/stm32f1.dtsi:327 */
			};
		};

		/* node '/soc/timers@40000400' defined in zephyr/dts/arm/st/f1/stm32f1.dtsi:331 */
		timers3: timers@40000400 {
			compatible = "st,stm32-timers"; /* in zephyr/dts/arm/st/f1/stm32f1.dtsi:332 */
			reg = < 0x40000400 0x400 >;     /* in zephyr/dts/arm/st/f1/stm32f1.dtsi:333 */
			clocks = < &rcc 0x1c 0x2 >,
			         < &rcc 0x8 0xff >;     /* in zephyr/dts/arm/st/f1/stm32f1.dtsi:334 */
			resets = < &rctl 0x201 >;       /* in zephyr/dts/arm/st/f1/stm32f1.dtsi:336 */
			interrupts = < 0x1d 0x0 >;      /* in zephyr/dts/arm/st/f1/stm32f1.dtsi:337 */
			interrupt-names = "global";     /* in zephyr/dts/arm/st/f1/stm32f1.dtsi:338 */
			st,prescaler = < 0x0 >;         /* in zephyr/dts/arm/st/f1/stm32f1.dtsi:339 */
			status = "disabled";            /* in zephyr/dts/arm/st/f1/stm32f1.dtsi:340 */

			/* node '/soc/timers@40000400/pwm' defined in zephyr/dts/arm/st/f1/stm32f1.dtsi:342 */
			pwm {
				compatible = "st,stm32-pwm"; /* in zephyr/dts/arm/st/f1/stm32f1.dtsi:343 */
				status = "disabled";         /* in zephyr/dts/arm/st/f1/stm32f1.dtsi:344 */
				#pwm-cells = < 0x3 >;        /* in zephyr/dts/arm/st/f1/stm32f1.dtsi:345 */
			};

			/* node '/soc/timers@40000400/counter' defined in zephyr/dts/arm/st/f1/stm32f1.dtsi:348 */
			counter {
				compatible = "st,stm32-counter"; /* in zephyr/dts/arm/st/f1/stm32f1.dtsi:349 */
				status = "disabled";             /* in zephyr/dts/arm/st/f1/stm32f1.dtsi:350 */
			};

			/* node '/soc/timers@40000400/qdec' defined in zephyr/dts/arm/st/f1/stm32f1.dtsi:353 */
			qdec {
				compatible = "st,stm32-qdec";    /* in zephyr/dts/arm/st/f1/stm32f1.dtsi:354 */
				st,input-filter-level = < 0x0 >; /* in zephyr/dts/arm/st/f1/stm32f1.dtsi:355 */
				status = "disabled";             /* in zephyr/dts/arm/st/f1/stm32f1.dtsi:356 */
			};
		};

		/* node '/soc/timers@40000800' defined in zephyr/dts/arm/st/f1/stm32f1.dtsi:360 */
		timers4: timers@40000800 {
			compatible = "st,stm32-timers"; /* in zephyr/dts/arm/st/f1/stm32f1.dtsi:361 */
			reg = < 0x40000800 0x400 >;     /* in zephyr/dts/arm/st/f1/stm32f1.dtsi:362 */
			clocks = < &rcc 0x1c 0x4 >,
			         < &rcc 0x8 0xff >;     /* in zephyr/dts/arm/st/f1/stm32f1.dtsi:363 */
			resets = < &rctl 0x202 >;       /* in zephyr/dts/arm/st/f1/stm32f1.dtsi:365 */
			interrupts = < 0x1e 0x0 >;      /* in zephyr/dts/arm/st/f1/stm32f1.dtsi:366 */
			interrupt-names = "global";     /* in zephyr/dts/arm/st/f1/stm32f1.dtsi:367 */
			st,prescaler = < 0x0 >;         /* in zephyr/dts/arm/st/f1/stm32f1.dtsi:368 */
			status = "disabled";            /* in zephyr/dts/arm/st/f1/stm32f1.dtsi:369 */

			/* node '/soc/timers@40000800/pwm' defined in zephyr/dts/arm/st/f1/stm32f1.dtsi:371 */
			pwm {
				compatible = "st,stm32-pwm"; /* in zephyr/dts/arm/st/f1/stm32f1.dtsi:372 */
				status = "disabled";         /* in zephyr/dts/arm/st/f1/stm32f1.dtsi:373 */
				#pwm-cells = < 0x3 >;        /* in zephyr/dts/arm/st/f1/stm32f1.dtsi:374 */
			};

			/* node '/soc/timers@40000800/counter' defined in zephyr/dts/arm/st/f1/stm32f1.dtsi:377 */
			counter {
				compatible = "st,stm32-counter"; /* in zephyr/dts/arm/st/f1/stm32f1.dtsi:378 */
				status = "disabled";             /* in zephyr/dts/arm/st/f1/stm32f1.dtsi:379 */
			};

			/* node '/soc/timers@40000800/qdec' defined in zephyr/dts/arm/st/f1/stm32f1.dtsi:382 */
			qdec {
				compatible = "st,stm32-qdec";    /* in zephyr/dts/arm/st/f1/stm32f1.dtsi:383 */
				st,input-filter-level = < 0x0 >; /* in zephyr/dts/arm/st/f1/stm32f1.dtsi:384 */
				status = "disabled";             /* in zephyr/dts/arm/st/f1/stm32f1.dtsi:385 */
			};
		};

		/* node '/soc/rtc@40002800' defined in zephyr/dts/arm/st/f1/stm32f1.dtsi:389 */
		rtc: rtc@40002800 {
			compatible = "st,stm32-rtc";       /* in zephyr/dts/arm/st/f1/stm32f1.dtsi:390 */
			reg = < 0x40002800 0x400 >;        /* in zephyr/dts/arm/st/f1/stm32f1.dtsi:391 */
			interrupts = < 0x29 0x0 >;         /* in zephyr/dts/arm/st/f1/stm32f1.dtsi:392 */
			clocks = < &rcc 0x1c 0x10000000 >; /* in zephyr/dts/arm/st/f1/stm32f1.dtsi:393 */
			prescaler = < 0x8000 >;            /* in zephyr/dts/arm/st/f1/stm32f1.dtsi:394 */
			status = "disabled";               /* in zephyr/dts/arm/st/f1/stm32f1.dtsi:395 */
		};

		/* node '/soc/adc@40012400' defined in zephyr/dts/arm/st/f1/stm32f1.dtsi:398 */
		adc1: adc@40012400 {
			compatible = "st,stm32f1-adc",
			             "st,stm32-adc";                               /* in zephyr/dts/arm/st/f1/stm32f1.dtsi:399 */
			reg = < 0x40012400 0x400 >;                                /* in zephyr/dts/arm/st/f1/stm32f1.dtsi:400 */
			clocks = < &rcc 0x18 0x200 >;                              /* in zephyr/dts/arm/st/f1/stm32f1.dtsi:401 */
			clock-names = "adcx";                                      /* in zephyr/dts/arm/st/f1/stm32f1.dtsi:402 */
			interrupts = < 0x12 0x0 >;                                 /* in zephyr/dts/arm/st/f1/stm32f1.dtsi:403 */
			#io-channel-cells = < 0x1 >;                               /* in zephyr/dts/arm/st/f1/stm32f1.dtsi:404 */
			st,adc-resolutions = < 0xc >;                              /* in zephyr/dts/arm/st/f1/stm32f1.dtsi:405 */
			sampling-times = < 0x2 0x8 0xe 0x1d 0x2a 0x38 0x48 0xf0 >; /* in zephyr/dts/arm/st/f1/stm32f1.dtsi:406 */
			st,adc-sequencer = "programmable";                         /* in zephyr/dts/arm/st/f1/stm32f1.dtsi:407 */
			st,adc-oversampler = "none";                               /* in zephyr/dts/arm/st/f1/stm32f1.dtsi:408 */
			st,adc-internal-regulator = "none";                        /* in zephyr/dts/arm/st/f1/stm32f1.dtsi:409 */
			pinctrl-0 = < &adc1_in0_pa0 >;                             /* in zephyr/boards/others/stm32_min_dev/stm32_min_dev.dts:123 */
			pinctrl-names = "default";                                 /* in zephyr/boards/others/stm32_min_dev/stm32_min_dev.dts:124 */
			status = "okay";                                           /* in zephyr/boards/others/stm32_min_dev/stm32_min_dev.dts:125 */
			phandle = < 0x20 >;                                        /* in zephyr/dts/arm/st/f1/stm32f1.dtsi:441 */
		};

		/* node '/soc/dma@40020000' defined in zephyr/dts/arm/st/f1/stm32f1.dtsi:413 */
		dma1: dma@40020000 {
			compatible = "st,stm32-dma-v2bis";                                          /* in zephyr/dts/arm/st/f1/stm32f1.dtsi:414 */
			#dma-cells = < 0x2 >;                                                       /* in zephyr/dts/arm/st/f1/stm32f1.dtsi:415 */
			reg = < 0x40020000 0x400 >;                                                 /* in zephyr/dts/arm/st/f1/stm32f1.dtsi:416 */
			clocks = < &rcc 0x14 0x1 >;                                                 /* in zephyr/dts/arm/st/f1/stm32f1.dtsi:417 */
			interrupts = < 0xb 0x0 0xc 0x0 0xd 0x0 0xe 0x0 0xf 0x0 0x10 0x0 0x11 0x0 >; /* in zephyr/dts/arm/st/f1/stm32f1.dtsi:418 */
			status = "disabled";                                                        /* in zephyr/dts/arm/st/f1/stm32f1.dtsi:419 */
		};

		/* node '/soc/spi@40003800' defined in zephyr/dts/arm/st/f1/stm32f103X8.dtsi:27 */
		spi2: spi@40003800 {
			compatible = "st,stm32-spi";                                                                               /* in zephyr/dts/arm/st/f1/stm32f103X8.dtsi:28 */
			#address-cells = < 0x1 >;                                                                                  /* in zephyr/dts/arm/st/f1/stm32f103X8.dtsi:29 */
			#size-cells = < 0x0 >;                                                                                     /* in zephyr/dts/arm/st/f1/stm32f103X8.dtsi:30 */
			reg = < 0x40003800 0x400 >;                                                                                /* in zephyr/dts/arm/st/f1/stm32f103X8.dtsi:31 */
			clocks = < &rcc 0x1c 0x4000 >;                                                                             /* in zephyr/dts/arm/st/f1/stm32f103X8.dtsi:32 */
			interrupts = < 0x24 0x5 >;                                                                                 /* in zephyr/dts/arm/st/f1/stm32f103X8.dtsi:33 */
			st,spi-data-width = "limited-8-16-bit";                                                                    /* in zephyr/dts/arm/st/f1/stm32f103X8.dtsi:34 */
			pinctrl-0 = < &spi2_nss_master_pb12 &spi2_sck_master_pb13 &spi2_miso_master_pb14 &spi2_mosi_master_pb15 >; /* in zephyr/boards/others/stm32_min_dev/stm32_min_dev.dts:100 */
			pinctrl-names = "default";                                                                                 /* in zephyr/boards/others/stm32_min_dev/stm32_min_dev.dts:102 */
			status = "okay";                                                                                           /* in zephyr/boards/others/stm32_min_dev/stm32_min_dev.dts:103 */
		};

		/* node '/soc/usb@40005c00' defined in zephyr/dts/arm/st/f1/stm32f103X8.dtsi:38 */
		usb: zephyr_udc0: usb@40005c00 {
			compatible = "st,stm32-usb";               /* in zephyr/dts/arm/st/f1/stm32f103X8.dtsi:39 */
			reg = < 0x40005c00 0x400 >;                /* in zephyr/dts/arm/st/f1/stm32f103X8.dtsi:40 */
			interrupts = < 0x14 0x0 >;                 /* in zephyr/dts/arm/st/f1/stm32f103X8.dtsi:41 */
			interrupt-names = "usb";                   /* in zephyr/dts/arm/st/f1/stm32f103X8.dtsi:42 */
			num-bidir-endpoints = < 0x8 >;             /* in zephyr/dts/arm/st/f1/stm32f103X8.dtsi:43 */
			ram-size = < 0x200 >;                      /* in zephyr/dts/arm/st/f1/stm32f103X8.dtsi:44 */
			maximum-speed = "full-speed";              /* in zephyr/dts/arm/st/f1/stm32f103X8.dtsi:45 */
			clocks = < &rcc 0x1c 0x800000 >;           /* in zephyr/dts/arm/st/f1/stm32f103X8.dtsi:47 */
			phys = < &usb_fs_phy >;                    /* in zephyr/dts/arm/st/f1/stm32f103X8.dtsi:48 */
			pinctrl-0 = < &usb_dm_pa11 &usb_dp_pa12 >; /* in zephyr/boards/others/stm32_min_dev/stm32_min_dev.dts:117 */
			pinctrl-names = "default";                 /* in zephyr/boards/others/stm32_min_dev/stm32_min_dev.dts:118 */
			status = "okay";                           /* in zephyr/boards/others/stm32_min_dev/stm32_min_dev.dts:119 */

			/* node '/soc/usb@40005c00/cdc_acm_uart0' defined in zephyer_stm32f103_blink/app.overlay:10 */
			cdc_acm_uart0: cdc_acm_uart0 {
				compatible = "zephyr,cdc-acm-uart"; /* in zephyer_stm32f103_blink/app.overlay:11 */
			};
		};

		/* node '/soc/can@40006400' defined in zephyr/dts/arm/st/f1/stm32f103X8.dtsi:51 */
		can1: can@40006400 {
			compatible = "st,stm32-bxcan";    /* in zephyr/dts/arm/st/f1/stm32f103X8.dtsi:52 */
			reg = < 0x40006400 0x400 >;       /* in zephyr/dts/arm/st/f1/stm32f103X8.dtsi:53 */
			interrupts = < 0x13 0x0 >,
			             < 0x14 0x0 >,
			             < 0x15 0x0 >,
			             < 0x16 0x0 >;        /* in zephyr/dts/arm/st/f1/stm32f103X8.dtsi:54 */
			interrupt-names = "TX",
			                  "RX0",
			                  "RX1",
			                  "SCE";          /* in zephyr/dts/arm/st/f1/stm32f103X8.dtsi:55 */
			clocks = < &rcc 0x1c 0x2000000 >; /* in zephyr/dts/arm/st/f1/stm32f103X8.dtsi:56 */
			status = "disabled";              /* in zephyr/dts/arm/st/f1/stm32f103X8.dtsi:57 */
		};
	};

	/* node '/cpus' defined in zephyr/dts/arm/st/f1/stm32f1.dtsi:28 */
	cpus {
		#address-cells = < 0x1 >; /* in zephyr/dts/arm/st/f1/stm32f1.dtsi:29 */
		#size-cells = < 0x0 >;    /* in zephyr/dts/arm/st/f1/stm32f1.dtsi:30 */

		/* node '/cpus/cpu@0' defined in zephyr/dts/arm/st/f1/stm32f1.dtsi:32 */
		cpu0: cpu@0 {
			device_type = "cpu";                  /* in zephyr/dts/arm/st/f1/stm32f1.dtsi:33 */
			compatible = "arm,cortex-m3";         /* in zephyr/dts/arm/st/f1/stm32f1.dtsi:34 */
			cpu-power-states = < &stop0 &stop1 >; /* in zephyr/dts/arm/st/f1/stm32f1.dtsi:35 */
			reg = < 0x0 >;                        /* in zephyr/dts/arm/st/f1/stm32f1.dtsi:36 */
		};

		/* node '/cpus/power-states' defined in zephyr/dts/arm/st/f1/stm32f1.dtsi:39 */
		power-states {

			/* node '/cpus/power-states/stop0' defined in zephyr/dts/arm/st/f1/stm32f1.dtsi:40 */
			stop0: stop0 {
				compatible = "zephyr,power-state";    /* in zephyr/dts/arm/st/f1/stm32f1.dtsi:41 */
				power-state-name = "suspend-to-idle"; /* in zephyr/dts/arm/st/f1/stm32f1.dtsi:42 */
				substate-id = < 0x0 >;                /* in zephyr/dts/arm/st/f1/stm32f1.dtsi:43 */
				min-residency-us = < 0xf4240 >;       /* in zephyr/dts/arm/st/f1/stm32f1.dtsi:44 */
				exit-latency-us = < 0x190 >;          /* in zephyr/dts/arm/st/f1/stm32f1.dtsi:45 */
				phandle = < 0x1c >;                   /* in zephyr/dts/arm/st/f1/stm32f1.dtsi:35 */
			};

			/* node '/cpus/power-states/stop1' defined in zephyr/dts/arm/st/f1/stm32f1.dtsi:48 */
			stop1: stop1 {
				compatible = "zephyr,power-state";    /* in zephyr/dts/arm/st/f1/stm32f1.dtsi:49 */
				power-state-name = "suspend-to-idle"; /* in zephyr/dts/arm/st/f1/stm32f1.dtsi:50 */
				substate-id = < 0x1 >;                /* in zephyr/dts/arm/st/f1/stm32f1.dtsi:51 */
				min-residency-us = < 0xf4240 >;       /* in zephyr/dts/arm/st/f1/stm32f1.dtsi:52 */
				exit-latency-us = < 0x258 >;          /* in zephyr/dts/arm/st/f1/stm32f1.dtsi:53 */
				phandle = < 0x1d >;                   /* in zephyr/dts/arm/st/f1/stm32f1.dtsi:35 */
			};
		};
	};

	/* node '/memory@20000000' defined in zephyr/dts/arm/st/f1/stm32f1.dtsi:58 */
	sram0: memory@20000000 {
		compatible = "zephyr,memory-region",
		             "mmio-sram";            /* in zephyr/dts/arm/st/f1/stm32f1.dtsi:59 */
		zephyr,memory-region = "SRAM0";      /* in zephyr/dts/arm/st/f1/stm32f1.dtsi:60 */
		reg = < 0x20000000 0x5000 >;         /* in zephyr/dts/arm/st/f1/stm32f103X8.dtsi:11 */
	};

	/* node '/clocks' defined in zephyr/dts/arm/st/f1/stm32f1.dtsi:63 */
	clocks {

		/* node '/clocks/clk-hse' defined in zephyr/dts/arm/st/f1/stm32f1.dtsi:64 */
		clk_hse: clk-hse {
			#clock-cells = < 0x0 >;            /* in zephyr/dts/arm/st/f1/stm32f1.dtsi:65 */
			compatible = "st,stm32-hse-clock"; /* in zephyr/dts/arm/st/f1/stm32f1.dtsi:66 */
			clock-frequency = < 0x7a1200 >;    /* in zephyr/boards/others/stm32_min_dev/stm32_min_dev.dts:38 */
			status = "okay";                   /* in zephyr/boards/others/stm32_min_dev/stm32_min_dev.dts:39 */
			phandle = < 0x1e >;                /* in zephyr/boards/others/stm32_min_dev/stm32_min_dev.dts:44 */
		};

		/* node '/clocks/clk-hsi' defined in zephyr/dts/arm/st/f1/stm32f1.dtsi:70 */
		clk_hsi: clk-hsi {
			#clock-cells = < 0x0 >;         /* in zephyr/dts/arm/st/f1/stm32f1.dtsi:71 */
			compatible = "fixed-clock";     /* in zephyr/dts/arm/st/f1/stm32f1.dtsi:72 */
			clock-frequency = < 0x7a1200 >; /* in zephyr/dts/arm/st/f1/stm32f1.dtsi:73 */
			status = "disabled";            /* in zephyr/dts/arm/st/f1/stm32f1.dtsi:74 */
		};

		/* node '/clocks/clk-lse' defined in zephyr/dts/arm/st/f1/stm32f1.dtsi:77 */
		clk_lse: clk-lse {
			#clock-cells = < 0x0 >;       /* in zephyr/dts/arm/st/f1/stm32f1.dtsi:78 */
			compatible = "fixed-clock";   /* in zephyr/dts/arm/st/f1/stm32f1.dtsi:79 */
			clock-frequency = < 0x8000 >; /* in zephyr/dts/arm/st/f1/stm32f1.dtsi:80 */
			status = "disabled";          /* in zephyr/dts/arm/st/f1/stm32f1.dtsi:81 */
		};

		/* node '/clocks/clk-lsi' defined in zephyr/dts/arm/st/f1/stm32f1.dtsi:84 */
		clk_lsi: clk-lsi {
			#clock-cells = < 0x0 >;       /* in zephyr/dts/arm/st/f1/stm32f1.dtsi:85 */
			compatible = "fixed-clock";   /* in zephyr/dts/arm/st/f1/stm32f1.dtsi:86 */
			clock-frequency = < 0x9c40 >; /* in zephyr/dts/arm/st/f1/stm32f1.dtsi:87 */
			status = "disabled";          /* in zephyr/dts/arm/st/f1/stm32f1.dtsi:88 */
		};

		/* node '/clocks/pll' defined in zephyr/dts/arm/st/f1/stm32f1.dtsi:91 */
		pll: pll {
			#clock-cells = < 0x0 >;              /* in zephyr/dts/arm/st/f1/stm32f1.dtsi:92 */
			compatible = "st,stm32f1-pll-clock"; /* in zephyr/dts/arm/st/f1/stm32f1.dtsi:93 */
			mul = < 0x9 >;                       /* in zephyr/boards/others/stm32_min_dev/stm32_min_dev.dts:43 */
			clocks = < &clk_hse >;               /* in zephyr/boards/others/stm32_min_dev/stm32_min_dev.dts:44 */
			status = "okay";                     /* in zephyr/boards/others/stm32_min_dev/stm32_min_dev.dts:45 */
			phandle = < 0x3 >;                   /* in zephyr/boards/others/stm32_min_dev/stm32_min_dev.dts:49 */
		};
	};

	/* node '/mcos' defined in zephyr/dts/arm/st/f1/stm32f1.dtsi:98 */
	mcos {

		/* node '/mcos/mco1' defined in zephyr/dts/arm/st/f1/stm32f1.dtsi:99 */
		mco1: mco1 {
			compatible = "st,stm32f1-clock-mco"; /* in zephyr/dts/arm/st/f1/stm32f1.dtsi:100 */
			status = "disabled";                 /* in zephyr/dts/arm/st/f1/stm32f1.dtsi:101 */
		};
	};

	/* node '/power@40007000' defined in zephyr/dts/arm/st/f1/stm32f1.dtsi:423 */
	pwr: power@40007000 {
		compatible = "st,stm32-pwr"; /* in zephyr/dts/arm/st/f1/stm32f1.dtsi:424 */
		reg = < 0x40007000 0x400 >;  /* in zephyr/dts/arm/st/f1/stm32f1.dtsi:425 */
		status = "disabled";         /* in zephyr/dts/arm/st/f1/stm32f1.dtsi:426 */
		wkup-pins-nb = < 0x1 >;      /* in zephyr/dts/arm/st/f1/stm32f1.dtsi:428 */
		#address-cells = < 0x1 >;    /* in zephyr/dts/arm/st/f1/stm32f1.dtsi:430 */
		#size-cells = < 0x0 >;       /* in zephyr/dts/arm/st/f1/stm32f1.dtsi:431 */

		/* node '/power@40007000/wkup-pin@1' defined in zephyr/dts/arm/st/f1/stm32f1.dtsi:433 */
		wkup-pin@1 {
			reg = < 0x1 >;                   /* in zephyr/dts/arm/st/f1/stm32f1.dtsi:434 */
			wkup-gpios = < &gpioa 0x0 0x1 >; /* in zephyr/dts/arm/st/f1/stm32f1.dtsi:435 */
		};
	};

	/* node '/dietemp' defined in zephyr/dts/arm/st/f1/stm32f1.dtsi:439 */
	die_temp: dietemp {
		compatible = "st,stm32-temp"; /* in zephyr/dts/arm/st/f1/stm32f1.dtsi:440 */
		io-channels = < &adc1 0x10 >; /* in zephyr/dts/arm/st/f1/stm32f1.dtsi:441 */
		status = "disabled";          /* in zephyr/dts/arm/st/f1/stm32f1.dtsi:442 */
		avgslope = "4.3";             /* in zephyr/dts/arm/st/f1/stm32f1.dtsi:443 */
		v25 = < 0x596 >;              /* in zephyr/dts/arm/st/f1/stm32f1.dtsi:444 */
		ntc;                          /* in zephyr/dts/arm/st/f1/stm32f1.dtsi:445 */
	};

	/* node '/smbus1' defined in zephyr/dts/arm/st/f1/stm32f1.dtsi:448 */
	smbus1: smbus1 {
		compatible = "st,stm32-smbus"; /* in zephyr/dts/arm/st/f1/stm32f1.dtsi:449 */
		#address-cells = < 0x1 >;      /* in zephyr/dts/arm/st/f1/stm32f1.dtsi:450 */
		#size-cells = < 0x0 >;         /* in zephyr/dts/arm/st/f1/stm32f1.dtsi:451 */
		i2c = < &i2c1 >;               /* in zephyr/dts/arm/st/f1/stm32f1.dtsi:452 */
		status = "disabled";           /* in zephyr/dts/arm/st/f1/stm32f1.dtsi:453 */
	};

	/* node '/smbus2' defined in zephyr/dts/arm/st/f1/stm32f1.dtsi:456 */
	smbus2: smbus2 {
		compatible = "st,stm32-smbus"; /* in zephyr/dts/arm/st/f1/stm32f1.dtsi:457 */
		#address-cells = < 0x1 >;      /* in zephyr/dts/arm/st/f1/stm32f1.dtsi:458 */
		#size-cells = < 0x0 >;         /* in zephyr/dts/arm/st/f1/stm32f1.dtsi:459 */
		i2c = < &i2c2 >;               /* in zephyr/dts/arm/st/f1/stm32f1.dtsi:460 */
		status = "disabled";           /* in zephyr/dts/arm/st/f1/stm32f1.dtsi:461 */
	};

	/* node '/usbphy' defined in zephyr/dts/arm/st/f1/stm32f103X8.dtsi:61 */
	usb_fs_phy: usbphy {
		compatible = "usb-nop-xceiv"; /* in zephyr/dts/arm/st/f1/stm32f103X8.dtsi:62 */
		#phy-cells = < 0x0 >;         /* in zephyr/dts/arm/st/f1/stm32f103X8.dtsi:63 */
		phandle = < 0x19 >;           /* in zephyr/dts/arm/st/f1/stm32f103X8.dtsi:48 */
	};

	/* node '/leds' defined in zephyr/boards/others/stm32_min_dev/stm32_min_dev.dts:23 */
	leds {
		compatible = "gpio-leds"; /* in zephyr/boards/others/stm32_min_dev/stm32_min_dev.dts:24 */

		/* node '/leds/led' defined in zephyr/boards/others/stm32_min_dev/stm32_min_dev.dts:26 */
		led: led {
			label = "LD";               /* in zephyr/boards/others/stm32_min_dev/stm32_min_dev.dts:28 */
			gpios = < &gpioc 0xd 0x1 >; /* in zephyr/boards/others/stm32_min_dev/stm32_min_dev_stm32f103xb_blue.overlay:13 */
		};
	};
};
